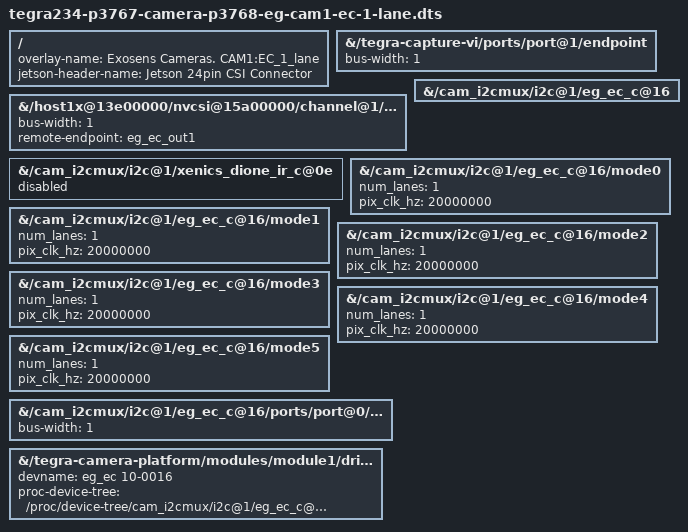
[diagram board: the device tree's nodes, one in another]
// SPDX-License-Identifier: GPL-2.0-only


/dts-v1/;
/plugin/;

#include <dt-common/jetson/tegra234-p3767-0000-common.h>

/ {
	overlay-name = "Exosens Cameras. CAM1:EC_1_lane";
	jetson-header-name = "Jetson 24pin CSI Connector";
	compatible = JETSON_COMPATIBLE_P3768;

	fragment@10 {
		target-path = "/tegra-capture-vi/ports/port@1/endpoint";
		__overlay__ {
			bus-width=<1>;
		};
	};

	fragment@11 {
		target-path = "/host1x@13e00000/nvcsi@15a00000/channel@1/ports/port@0/endpoint@2";
		__overlay__ {
			bus-width=<1>;
         remote-endpoint = <&eg_ec_out1>;
		};
	};

   // Disable Dione cameras
	fragment@12 {
		target-path = "/cam_i2cmux/i2c@1/xenics_dione_ir_c@0e";
		__overlay__ {
         status = "disabled";
		};
	};

   // Enable EngineCore cameras
	fragment@13 {
		target-path = "/cam_i2cmux/i2c@1/eg_ec_c@16";
		__overlay__ {
         status = "okay";
		};
	};
	fragment@14 {   
		target-path = "/cam_i2cmux/i2c@1/eg_ec_c@16/mode0";
		__overlay__ {
         num_lanes = "1";
         pix_clk_hz = "20000000";
		};
	};
	fragment@15 {
		target-path = "/cam_i2cmux/i2c@1/eg_ec_c@16/mode1";
		__overlay__ {
         num_lanes = "1";
         pix_clk_hz = "20000000";
		};
	};
	fragment@16 {
		target-path = "/cam_i2cmux/i2c@1/eg_ec_c@16/mode2";
		__overlay__ {
         num_lanes = "1";
         pix_clk_hz = "20000000";
		};
	};
	fragment@17 {
		target-path = "/cam_i2cmux/i2c@1/eg_ec_c@16/mode3";
		__overlay__ {
         num_lanes = "1";
         pix_clk_hz = "20000000";
		};
	};
	fragment@18 {
		target-path = "/cam_i2cmux/i2c@1/eg_ec_c@16/mode4";
		__overlay__ {
         num_lanes = "1";
         pix_clk_hz = "20000000";
		};
	};
	fragment@19 {
		target-path = "/cam_i2cmux/i2c@1/eg_ec_c@16/mode5";
		__overlay__ {
         num_lanes = "1";
         pix_clk_hz = "20000000";
		};
	};
	fragment@20 {
		target-path = "/cam_i2cmux/i2c@1/eg_ec_c@16/ports/port@0/endpoint";
		__overlay__ {
			bus-width=<1>;
		};
	};

	fragment@21 {
		target-path = "/tegra-camera-platform/modules/module1/drivernode0";
		__overlay__ {
         devname = "eg_ec 10-0016";
			proc-device-tree = "/proc/device-tree/cam_i2cmux/i2c@1/eg_ec_c@16";
		};
	};


};
